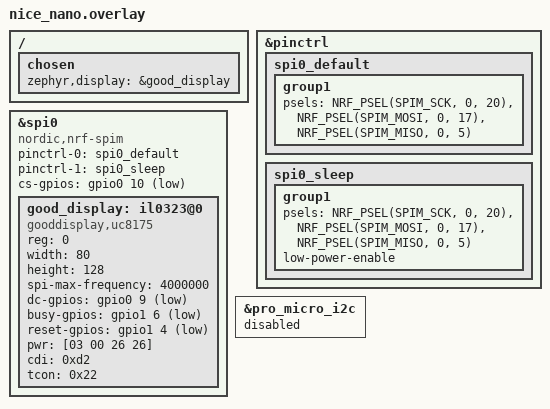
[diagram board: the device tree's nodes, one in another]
/*
 * Copyright (c) 2024 The ZMK Contributors
 * SPDX-License-Identifier: MIT
 */

&pinctrl {
  spi0_default: spi0_default {
    group1 {
      psels = <NRF_PSEL(SPIM_SCK, 0, 20)>,
        <NRF_PSEL(SPIM_MOSI, 0, 17)>,
        <NRF_PSEL(SPIM_MISO, 0, 5)>;
    };
  };

  spi0_sleep: spi0_sleep {
    group1 {
      psels = <NRF_PSEL(SPIM_SCK, 0, 20)>,
        <NRF_PSEL(SPIM_MOSI, 0, 17)>,
        <NRF_PSEL(SPIM_MISO, 0, 5)>;
      low-power-enable;
    };
  };
};

&spi0 {
  compatible = "nordic,nrf-spim";
  status = "okay";
  pinctrl-0 = <&spi0_default>;
  pinctrl-1 = <&spi0_sleep>;
  pinctrl-names = "default", "sleep";
  cs-gpios = <&gpio0 10 GPIO_ACTIVE_LOW>;

  good_display: il0323@0 {
    compatible = "gooddisplay,uc8175";
    reg =  <0>;
    width = <80>;
    height = <128>;
    spi-max-frequency = <4000000>;
    dc-gpios = <&gpio0 9 GPIO_ACTIVE_LOW>;
    busy-gpios = <&gpio1 6 GPIO_ACTIVE_LOW>;
    reset-gpios = <&gpio1 4 GPIO_ACTIVE_LOW>;
    pwr = [03 00 26 26];
    cdi = <0xd2>;
    tcon = <0x22>;
  };
};

&pro_micro_i2c {
  status = "disabled";
};

/ {
  chosen {
    zephyr,display = &good_display;
  };
};
